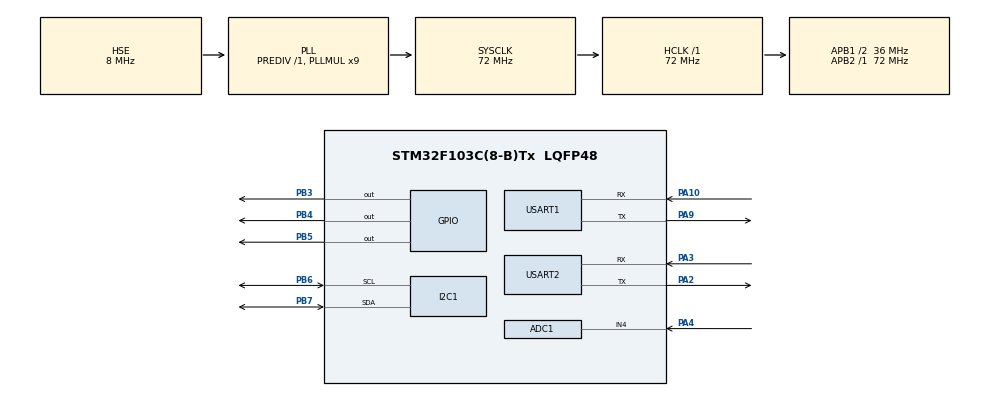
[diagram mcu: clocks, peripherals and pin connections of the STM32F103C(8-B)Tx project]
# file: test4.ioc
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ADC1.Channel-0\#ChannelRegularConversion=ADC_CHANNEL_4
ADC1.NbrOfConversionFlag=1
ADC1.Rank-0\#ChannelRegularConversion=1
ADC1.SamplingTime-0\#ChannelRegularConversion=ADC_SAMPLETIME_1CYCLE_5
ADC1.master=1
Mcu.Family=STM32F1
Mcu.Name=STM32F103C(8-B)Tx
Mcu.Package=LQFP48
NVIC.ADC1_2_IRQn=true\:0\:0\:false\:false\:true\:true\:true\:true
NVIC.PriorityGroup=NVIC_PRIORITYGROUP_4
NVIC.USART1_IRQn=true\:0\:0\:false\:false\:true\:true\:true\:true
PA10.Mode=Asynchronous
PA10.Signal=USART1_RX
PA13.Mode=Serial_Wire
PA13.Signal=SYS_JTMS-SWDIO
PA14.Mode=Serial_Wire
PA14.Signal=SYS_JTCK-SWCLK
PA2.Mode=Asynchronous
PA2.Signal=USART2_TX
PA3.Mode=Asynchronous
PA3.Signal=USART2_RX
PA4.Signal=ADCx_IN4
PA9.Mode=Asynchronous
PA9.Signal=USART1_TX
PB3.Signal=GPIO_Output
PB4.Signal=GPIO_Output
PB5.Signal=GPIO_Output
PB6.Mode=I2C
PB6.Signal=I2C1_SCL
PB7.Mode=I2C
PB7.Signal=I2C1_SDA
PD0-OSC_IN.Mode=HSE-External-Oscillator
PD0-OSC_IN.Signal=RCC_OSC_IN
PD1-OSC_OUT.Mode=HSE-External-Oscillator
PD1-OSC_OUT.Signal=RCC_OSC_OUT
ProjectManager.HeapSize=0x200
ProjectManager.StackSize=0x400
ProjectManager.TargetToolchain=STM32CubeIDE
RCC.AHBFreq_Value=72000000
RCC.APB1CLKDivider=RCC_HCLK_DIV2
RCC.APB1Freq_Value=36000000
RCC.APB1TimFreq_Value=72000000
RCC.APB2Freq_Value=72000000
RCC.APB2TimFreq_Value=72000000
RCC.HCLKFreq_Value=72000000
RCC.PLLMUL=RCC_PLL_MUL9
RCC.PLLSourceVirtual=RCC_PLLSOURCE_HSE
RCC.SYSCLKFreq_VALUE=72000000
RCC.SYSCLKSource=RCC_SYSCLKSOURCE_PLLCLK
RCC.USBFreq_Value=72000000
SH.ADCx_IN4.0=ADC1_IN4,IN4
USART1.Parity=PARITY_NONE
USART1.VirtualMode=VM_ASYNC
USART2.VirtualMode=VM_ASYNC
board=custom

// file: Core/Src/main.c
/* USER CODE BEGIN Header */
/**
  ******************************************************************************
  * @file           : main.c
  * @brief          : Main program body
  ******************************************************************************
  * @attention
  *
  * Copyright (c) 2023 STMicroelectronics.
  * All rights reserved.
  *
  * This software is licensed under terms that can be found in the LICENSE file
  * in the root directory of this software component.
  * If no LICENSE file comes with this software, it is provided AS-IS.
  *
  ******************************************************************************
  */
/* USER CODE END Header */
#include "main.h"

/* USER CODE BEGIN Includes */
#include <stdio.h>
#include <string.h>
#include "INA219.h"
/* USER CODE END Includes */

ADC_HandleTypeDef hadc1;

I2C_HandleTypeDef hi2c1;

UART_HandleTypeDef huart1;
UART_HandleTypeDef huart2;

void SystemClock_Config(void);
static void MX_GPIO_Init(void);
static void MX_I2C1_Init(void);
static void MX_USART1_UART_Init(void);
static void MX_USART2_UART_Init(void);
static void MX_ADC1_Init(void);

/* USER CODE BEGIN PFP */
INA219_t ina219;

uint16_t vbus, vshunt, current;
uint16_t temp = 0;
/* USER CODE END PFP */
void HAL_ADC_ConvCpltCallback(ADC_HandleTypeDef *hadc);

int main(void)
{
  /* USER CODE BEGIN 1 */
//	unit8_t UART_Buffer[20] ={0};
  /* USER CODE END 1 */

  /* MCU Configuration--------------------------------------------------------*/

  /* Reset of all peripherals, Initializes the Flash interface and the Systick. */
  HAL_Init();

  /* Configure the system clock */
  SystemClock_Config();

  /* Initialize all configured peripherals */
  MX_GPIO_Init();
  MX_I2C1_Init();
  MX_USART1_UART_Init();
  MX_USART2_UART_Init();
  MX_ADC1_Init();
  /* USER CODE BEGIN 2 */
  //INA219_setPowerMode(&ina219, INA219_CONFIG_MODE_ADCOFF);
  if (HAL_ADC_Start_IT(&hadc1) != HAL_OK)
    {
      Error_Handler();
    }

  /* USER CODE END 2 */

  /* Infinite loop */
  while (1)
  {
	  // Chờ cho quá trình chuyển đổi ADC hoàn thành
	  	  if (HAL_ADC_PollForConversion(&hadc1, 100) == HAL_OK) {
	  		  // Đọc giá trị từ ADC
	  	      uint32_t adcValue = HAL_ADC_GetValue(&hadc1);
	  	      // Chuyển đổi giá trị ADC sang giá trị nhiệt độ
	  	      temp = (adcValue * 3.3) / 4095;
	  	  }
	  	  	  	  vbus = (INA219_ReadBusVoltage(&ina219));
	  	  	  	  vshunt =  (INA219_ReadShuntVolage(&ina219));
	  	  	  	  current = INA219_ReadCurrent(&ina219);
	  	  	  	  	  	  char uartData[100];
	  	  		  	  	  sprintf(uartData, "T:%d\nSHUNT:%d\nBUS:%d,I:%d",temp,vbus, vshunt,current);
	  	  		  	  	  HAL_UART_Transmit(&huart1, (uint8_t *)uartData, strlen(uartData), HAL_MAX_DELAY);
	  	  		  	 	  HAL_Delay(1000);
	  	  // Đợi một khoảng thời gian trước khi đọc giá trị nhiệt độ tiếp theo

  }
}

void SystemClock_Config(void)
{
  RCC_OscInitTypeDef RCC_OscInitStruct = {0};
  RCC_ClkInitTypeDef RCC_ClkInitStruct = {0};
  RCC_PeriphCLKInitTypeDef PeriphClkInit = {0};

  /** Initializes the RCC Oscillators according to the specified parameters
  * in the RCC_OscInitTypeDef structure.
  */
  RCC_OscInitStruct.OscillatorType = RCC_OSCILLATORTYPE_HSE;
  RCC_OscInitStruct.HSEState = RCC_HSE_ON;
  RCC_OscInitStruct.HSEPredivValue = RCC_HSE_PREDIV_DIV1;
  RCC_OscInitStruct.HSIState = RCC_HSI_ON;
  RCC_OscInitStruct.PLL.PLLState = RCC_PLL_ON;
  RCC_OscInitStruct.PLL.PLLSource = RCC_PLLSOURCE_HSE;
  RCC_OscInitStruct.PLL.PLLMUL = RCC_PLL_MUL9;
  if (HAL_RCC_OscConfig(&RCC_OscInitStruct) != HAL_OK)
  {
    Error_Handler();
  }

  /** Initializes the CPU, AHB and APB buses clocks
  */
  RCC_ClkInitStruct.ClockType = RCC_CLOCKTYPE_HCLK|RCC_CLOCKTYPE_SYSCLK
                              |RCC_CLOCKTYPE_PCLK1|RCC_CLOCKTYPE_PCLK2;
  RCC_ClkInitStruct.SYSCLKSource = RCC_SYSCLKSOURCE_PLLCLK;
  RCC_ClkInitStruct.AHBCLKDivider = RCC_SYSCLK_DIV1;
  RCC_ClkInitStruct.APB1CLKDivider = RCC_HCLK_DIV2;
  RCC_ClkInitStruct.APB2CLKDivider = RCC_HCLK_DIV1;

  if (HAL_RCC_ClockConfig(&RCC_ClkInitStruct, FLASH_LATENCY_2) != HAL_OK)
  {
    Error_Handler();
  }
  PeriphClkInit.PeriphClockSelection = RCC_PERIPHCLK_ADC;
  PeriphClkInit.AdcClockSelection = RCC_ADCPCLK2_DIV2;
  if (HAL_RCCEx_PeriphCLKConfig(&PeriphClkInit) != HAL_OK)
  {
    Error_Handler();
  }
}

static void MX_ADC1_Init(void)
{

  ADC_ChannelConfTypeDef sConfig = {0};

  /** Common config
  */
  hadc1.Instance = ADC1;
  hadc1.Init.ScanConvMode = ADC_SCAN_DISABLE;
  hadc1.Init.ContinuousConvMode = DISABLE;
  hadc1.Init.DiscontinuousConvMode = DISABLE;
  hadc1.Init.ExternalTrigConv = ADC_SOFTWARE_START;
  hadc1.Init.DataAlign = ADC_DATAALIGN_RIGHT;
  hadc1.Init.NbrOfConversion = 1;
  if (HAL_ADC_Init(&hadc1) != HAL_OK)
  {
    Error_Handler();
  }

  /** Configure Regular Channel
  */
  sConfig.Channel = ADC_CHANNEL_4;
  sConfig.Rank = ADC_REGULAR_RANK_1;
  sConfig.SamplingTime = ADC_SAMPLETIME_1CYCLE_5;
  if (HAL_ADC_ConfigChannel(&hadc1, &sConfig) != HAL_OK)
  {
    Error_Handler();
  }

}

static void MX_I2C1_Init(void)
{

  hi2c1.Instance = I2C1;
  hi2c1.Init.ClockSpeed = 100000;
  hi2c1.Init.DutyCycle = I2C_DUTYCYCLE_2;
  hi2c1.Init.OwnAddress1 = 0;
  hi2c1.Init.AddressingMode = I2C_ADDRESSINGMODE_7BIT;
  hi2c1.Init.DualAddressMode = I2C_DUALADDRESS_DISABLE;
  hi2c1.Init.OwnAddress2 = 0;
  hi2c1.Init.GeneralCallMode = I2C_GENERALCALL_DISABLE;
  hi2c1.Init.NoStretchMode = I2C_NOSTRETCH_DISABLE;
  if (HAL_I2C_Init(&hi2c1) != HAL_OK)
  {
    Error_Handler();
  }

}

static void MX_USART1_UART_Init(void)
{

  huart1.Instance = USART1;
  huart1.Init.BaudRate = 115200;
  huart1.Init.WordLength = UART_WORDLENGTH_8B;
  huart1.Init.StopBits = UART_STOPBITS_1;
  huart1.Init.Parity = UART_PARITY_NONE;
  huart1.Init.Mode = UART_MODE_TX_RX;
  huart1.Init.HwFlowCtl = UART_HWCONTROL_NONE;
  huart1.Init.OverSampling = UART_OVERSAMPLING_16;
  if (HAL_UART_Init(&huart1) != HAL_OK)
  {
    Error_Handler();
  }

}

static void MX_USART2_UART_Init(void)
{

  huart2.Instance = USART2;
  huart2.Init.BaudRate = 115200;
  huart2.Init.WordLength = UART_WORDLENGTH_8B;
  huart2.Init.StopBits = UART_STOPBITS_1;
  huart2.Init.Parity = UART_PARITY_NONE;
  huart2.Init.Mode = UART_MODE_TX_RX;
  huart2.Init.HwFlowCtl = UART_HWCONTROL_NONE;
  huart2.Init.OverSampling = UART_OVERSAMPLING_16;
  if (HAL_UART_Init(&huart2) != HAL_OK)
  {
    Error_Handler();
  }

}

static void MX_GPIO_Init(void)
{
  GPIO_InitTypeDef GPIO_InitStruct = {0};

  /* GPIO Ports Clock Enable */
  __HAL_RCC_GPIOD_CLK_ENABLE();
  __HAL_RCC_GPIOA_CLK_ENABLE();
  __HAL_RCC_GPIOB_CLK_ENABLE();

  /*Configure GPIO pin Output Level */
  HAL_GPIO_WritePin(GPIOB, GPIO_PIN_3|GPIO_PIN_4|GPIO_PIN_5, GPIO_PIN_RESET);

  /*Configure GPIO pins : PB3 PB4 PB5 */
  GPIO_InitStruct.Pin = GPIO_PIN_3|GPIO_PIN_4|GPIO_PIN_5;
  GPIO_InitStruct.Mode = GPIO_MODE_OUTPUT_PP;
  GPIO_InitStruct.Pull = GPIO_NOPULL;
  GPIO_InitStruct.Speed = GPIO_SPEED_FREQ_LOW;
  HAL_GPIO_Init(GPIOB, &GPIO_InitStruct);

}

void Error_Handler(void)
{
  __disable_irq();
  while (1)
  {
  }
}

void HAL_ADC_ConvCpltCallback(ADC_HandleTypeDef *hadc)
{
	 if (hadc == &hadc1) {
	        // Đọc giá trị nhiệt độ từ ADC
	        uint32_t adcValue = HAL_ADC_GetValue(&hadc1);
	        float voltage = (float)adcValue/4095.0*3.3;

	        // Chuyển đổi giá trị ADC sang giá trị nhiệt độ
	        temp = voltage*10.0;
	        HAL_ADC_Start_IT(&hadc1);
	    }
}
